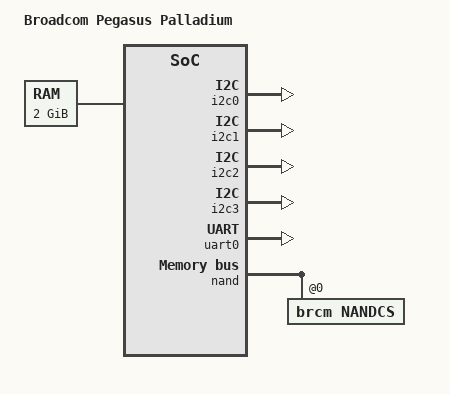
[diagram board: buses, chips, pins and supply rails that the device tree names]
/*
 *  BSD LICENSE
 *
 *  Copyright(c) 2015 Broadcom Corporation.  All rights reserved.
 *
 *  Redistribution and use in source and binary forms, with or without
 *  modification, are permitted provided that the following conditions
 *  are met:
 *
 *    * Redistributions of source code must retain the above copyright
 *      notice, this list of conditions and the following disclaimer.
 *    * Redistributions in binary form must reproduce the above copyright
 *      notice, this list of conditions and the following disclaimer in
 *      the documentation and/or other materials provided with the
 *      distribution.
 *    * Neither the name of Broadcom Corporation nor the names of its
 *      contributors may be used to endorse or promote products derived
 *      from this software without specific prior written permission.
 *
 *  THIS SOFTWARE IS PROVIDED BY THE COPYRIGHT HOLDERS AND CONTRIBUTORS
 *  "AS IS" AND ANY EXPRESS OR IMPLIED WARRANTIES, INCLUDING, BUT NOT
 *  LIMITED TO, THE IMPLIED WARRANTIES OF MERCHANTABILITY AND FITNESS FOR
 *  A PARTICULAR PURPOSE ARE DISCLAIMED. IN NO EVENT SHALL THE COPYRIGHT
 *  OWNER OR CONTRIBUTORS BE LIABLE FOR ANY DIRECT, INDIRECT, INCIDENTAL,
 *  SPECIAL, EXEMPLARY, OR CONSEQUENTIAL DAMAGES (INCLUDING, BUT NOT
 *  LIMITED TO, PROCUREMENT OF SUBSTITUTE GOODS OR SERVICES; LOSS OF USE,
 *  DATA, OR PROFITS; OR BUSINESS INTERRUPTION) HOWEVER CAUSED AND ON ANY
 *  THEORY OF LIABILITY, WHETHER IN CONTRACT, STRICT LIABILITY, OR TORT
 *  (INCLUDING NEGLIGENCE OR OTHERWISE) ARISING IN ANY WAY OUT OF THE USE
 * OF THIS SOFTWARE, EVEN IF ADVISED OF THE POSSIBILITY OF SUCH DAMAGE.
 */

/dts-v1/;

/* Reserve the cpu-release address */
/memreserve/ 0x84b00000 0x00000008;

#include "pegasus.dtsi"

/ {
	model = "Broadcom Pegasus Palladium";

	chosen {
		bootargs = "maxcpus=5 console=ttyS0,19200n8 debug \
earlycon=uart8250,mmio32,0x00300000 initrd=0x83000000,10M";
	};

	memory {
		device_type = "memory";
		reg = <0x000000000 0x80000000 0x00000000 0x80000000>;
	};

	cpus {
		cpu@000 {
			enable-method = "spin-table";
			cpu-release-addr = <0 0x84B00000>;
		};

		cpu@001 {
			enable-method = "spin-table";
			cpu-release-addr = <0 0x84B00000>;
		};

		cpu@002 {
			enable-method = "spin-table";
			cpu-release-addr = <0 0x84B00000>;
		};

		cpu@003 {
			enable-method = "spin-table";
			cpu-release-addr = <0 0x84B00000>;
		};

		cpu@100 {
			enable-method = "spin-table";
			cpu-release-addr = <0 0x84B00000>;
		};
	};
};

&i2c0 {
	status = "ok";
};

&i2c1 {
	status = "ok";
};

&i2c2 {
	status = "ok";
};

&i2c3 {
	status = "ok";
};

&uart0 {
	status = "ok";
};

&nand {
	nandcs@0 {
		compatible = "brcm,nandcs";
		reg = <0>;
		nand-ecc-mode = "hw";
		nand-ecc-strength = <8>;
		nand-ecc-step-size = <512>;
		#address-cells = <1>;
		#size-cells = <1>;
	};
};
